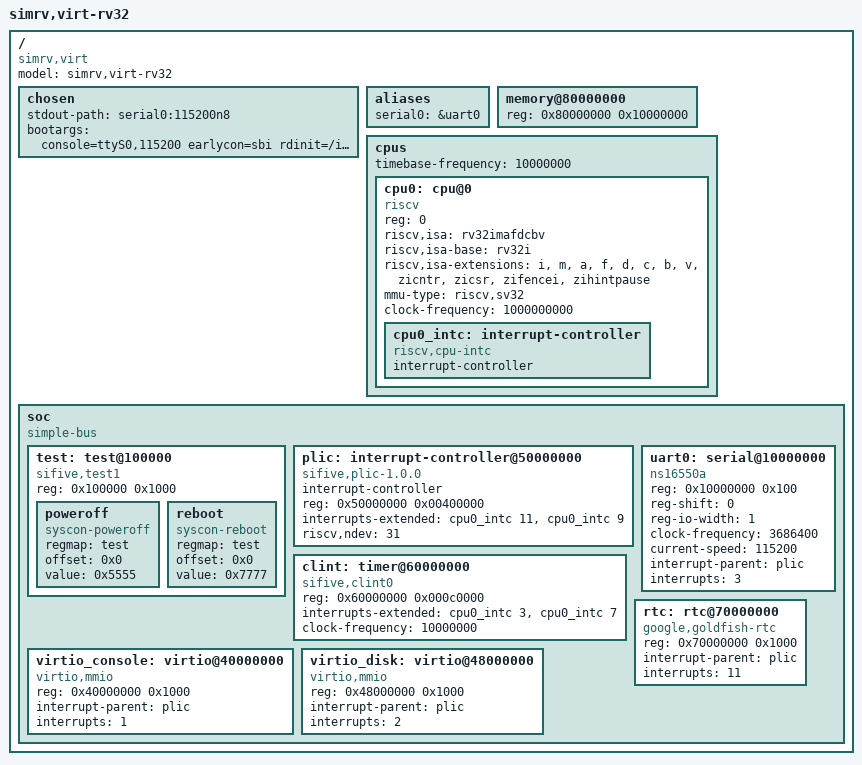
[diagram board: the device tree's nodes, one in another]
/dts-v1/;

/ {
    #address-cells = <1>;
    #size-cells = <1>;
    compatible = "simrv,virt";
    model = "simrv,virt-rv32";

    chosen {
        stdout-path = "serial0:115200n8";
        bootargs = "console=ttyS0,115200 earlycon=sbi rdinit=/init rw loglevel=7";
    };

    aliases {
        serial0 = &uart0;
    };

    memory@80000000 {
        device_type = "memory";
        reg = <0x80000000 0x10000000>;
    };

    cpus {
        #address-cells = <1>;
        #size-cells = <0>;
        timebase-frequency = <10000000>;

        cpu0: cpu@0 {
            compatible = "riscv";
            device_type = "cpu";
            reg = <0>;
            riscv,isa = "rv32imafdcbv";
            riscv,isa-base = "rv32i";
            riscv,isa-extensions = "i", "m", "a", "f", "d", "c", "b", "v", "zicntr", "zicsr", "zifencei", "zihintpause";
            mmu-type = "riscv,sv32";
            clock-frequency = <1000000000>;

            cpu0_intc: interrupt-controller {
                #interrupt-cells = <1>;
                #address-cells = <0>;
                compatible = "riscv,cpu-intc";
                interrupt-controller;
            };
        };
    };

    soc {
        #address-cells = <1>;
        #size-cells = <1>;
        compatible = "simple-bus";
        ranges;

        test: test@100000 {
            compatible = "sifive,test1", "sifive,test0", "syscon";
            reg = <0x100000 0x1000>;

            poweroff {
                compatible = "syscon-poweroff";
                regmap = <&test>;
                offset = <0x0>;
                value = <0x5555>;
            };

            reboot {
                compatible = "syscon-reboot";
                regmap = <&test>;
                offset = <0x0>;
                value = <0x7777>;
            };
        };

        plic: interrupt-controller@50000000 {
            #address-cells = <0>;
            #interrupt-cells = <1>;
            compatible = "sifive,plic-1.0.0", "riscv,plic0";
            interrupt-controller;
            reg = <0x50000000 0x00400000>;
            interrupts-extended = <&cpu0_intc 11 &cpu0_intc 9>;
            riscv,ndev = <31>;
        };

        clint: timer@60000000 {
            compatible = "sifive,clint0", "riscv,clint0";
            reg = <0x60000000 0x000c0000>;
            interrupts-extended = <&cpu0_intc 3 &cpu0_intc 7>;
            clock-frequency = <10000000>;
        };

        uart0: serial@10000000 {
            compatible = "ns16550a";
            reg = <0x10000000 0x100>;
            reg-shift = <0>;
            reg-io-width = <1>;
            clock-frequency = <3686400>;
            current-speed = <115200>;
            interrupt-parent = <&plic>;
            interrupts = <3>;
        };

        virtio_console: virtio@40000000 {
            compatible = "virtio,mmio";
            reg = <0x40000000 0x1000>;
            interrupt-parent = <&plic>;
            interrupts = <1>;
        };

        virtio_disk: virtio@48000000 {
            compatible = "virtio,mmio";
            reg = <0x48000000 0x1000>;
            interrupt-parent = <&plic>;
            interrupts = <2>;
        };

        rtc: rtc@70000000 {
            compatible = "google,goldfish-rtc";
            reg = <0x70000000 0x1000>;
            interrupt-parent = <&plic>;
            interrupts = <11>;
        };
    };
};
